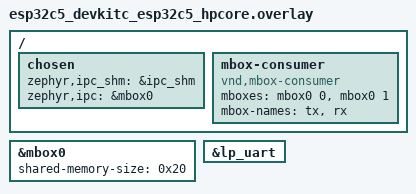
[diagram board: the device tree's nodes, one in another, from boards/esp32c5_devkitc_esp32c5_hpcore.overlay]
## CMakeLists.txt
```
# SPDX-License-Identifier: Apache-2.0

cmake_minimum_required(VERSION 3.20.0)
find_package(Zephyr REQUIRED HINTS $ENV{ZEPHYR_BASE})
project(zephyr_bist)

target_sources(app PRIVATE src/main.c)
```

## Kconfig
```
# Copyright (c) 2025 Espressif Systems (Shanghai) Co., Ltd.
# SPDX-License-Identifier: Apache-2.0

source "Kconfig.zephyr"

config INCLUDE_REMOTE_DIR
	bool "Include remote core header directory"
	help
	  Include remote build header files. Can be used if primary image
	  needs to be aware of size or base address of secondary image

config TX_ENABLED
	bool "TX enabled"
	default y
	help
	  Enable TX

config RX_ENABLED
	bool "RX enabled"
	default y
	help
	  Enable RX
```

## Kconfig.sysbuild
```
# Copyright (c) 2025 Espressif Systems (Shanghai) Co., Ltd.
# SPDX-License-Identifier: Apache-2.0

source "share/sysbuild/Kconfig"

config REMOTE_BOARD
	string "Remote board"
	default "esp32c6_devkitc/esp32c6/lpcore" if "$(BOARD)/${BOARD_QUALIFIERS}" = "esp32c6_devkitc/esp32c6/hpcore"
```

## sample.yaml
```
sample:
  name: ESP-BIST Host Diagnostics
  description: >
    LP-core Class B self-tests supervised from a Zephyr HP application, using
    the Host Diagnostic Agent and its LP companion.
common:
  sysbuild: true
  integration_platforms:
    - esp32c5_devkitc/esp32c5/hpcore
    - esp32c6_devkitc/esp32c6/hpcore
    - esp32p4x_function_ev_board/esp32p4/hpcore
  platform_allow:
    - esp32c5_devkitc/esp32c5/hpcore
    - esp32c6_devkitc/esp32c6/hpcore
    - esp32p4x_function_ev_board/esp32p4/hpcore
  tags:
    - bist
    - safety
tests:
  # Smoke test for the sample as shipped. The companion verdict is asserted in
  # tests/integration/hd_zephyr; here we only confirm the sample runs and
  # reports, so it stays a starting point rather than a test suite.
  sample.bist.host_diagnostics:
    harness: console
    harness_config:
      type: multi_line
      ordered: true
      regex:
        - "test_HD_agent_ready:PASS"
        - "test_BIST_cpu_reg:PASS"
        - "test_BIST_runtime_cpu_reg:PASS"
        - "Runtime loop 5/5"
        - "test_HD_audit_cpu:PASS"
        - "test_HD_audit_csr:PASS"
        - "test_HD_audit_ram:PASS"
        - "BIST_RESULT:PASS"
```

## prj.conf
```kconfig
CONFIG_MBOX=y
CONFIG_ESP32_ULP_COPROC_ENABLED=y
# Host Diagnostic Agent (HP side). LP runs the companion STL; HP compiles
# CPU/CSR/RAM STL slices when the matching HD audit is enabled.
CONFIG_ESP_BIST_HOST_DIAGNOSTICS=y
CONFIG_ESP_BIST_HD_AUDIT_QA=y
CONFIG_ESP_BIST_HD_AUDIT_CHECKPOINT=y
CONFIG_ESP_BIST_HD_AUDIT_IRQ_LATENCY=y
CONFIG_ESP_BIST_HD_AUDIT=y
CONFIG_ESP_BIST_HD_AUDIT_CPU=y
CONFIG_ESP_BIST_HD_AUDIT_CSR=y
CONFIG_ESP_BIST_HD_AUDIT_RAM=y
```

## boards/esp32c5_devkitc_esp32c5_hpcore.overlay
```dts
/*
 * Copyright (c) 2026 Espressif Systems (Shanghai) Co., Ltd.
 *
 * SPDX-License-Identifier: Apache-2.0
 */

/ {
	chosen {
		zephyr,ipc_shm = &ipc_shm;
		zephyr,ipc = &mbox0;
	};

	mbox-consumer {
		compatible = "vnd,mbox-consumer";
		mboxes = <&mbox0 0>, <&mbox0 1>;
		mbox-names = "tx", "rx";
	};
};

&mbox0 {
	status = "okay";
	/* One Host Diagnostics frame (4 words) per direction. */
	shared-memory-size = <0x20>;
};

&lp_uart {
	status = "okay";
};
```

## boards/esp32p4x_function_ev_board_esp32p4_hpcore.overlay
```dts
/*
 * Copyright (c) 2026 Espressif Systems (Shanghai) Co., Ltd.
 *
 * SPDX-License-Identifier: Apache-2.0
 */

/ {
	chosen {
		zephyr,ipc_shm = &ipc_shm;
		zephyr,ipc = &mbox0;
		zephyr,console = &uart0;
		zephyr,shell-uart = &uart0;
	};

	mbox-consumer {
		compatible = "vnd,mbox-consumer";
		mboxes = <&mbox0 0>, <&mbox0 1>;
		mbox-names = "tx", "rx";
	};
};

&mbox0 {
	status = "okay";
	shared-memory-size = <0x20>;
};

&lp_uart {
	status = "okay";
};
```

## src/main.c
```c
/*
 * Copyright (c) 2026 Espressif Systems (Shanghai) Co., Ltd.
 *
 * SPDX-License-Identifier: Apache-2.0
 */

/*
 * HP-core side of the ESP-BIST Zephyr sample.
 *
 * Starts the Host Diagnostic Agent, which sends AGENT_READY, queues the LP
 * companion status bitmasks and answers Q&A challenges on its worker thread.
 * The companion under remote/ does the actual testing; this side only reports.
 * Mirrors samples/idf/main/main.c so both platforms read the same way.
 *
 * This is the happy path only, so it stays readable as a starting point.
 * Fail-closed behaviour is validated in tests/integration/hd_zephyr, which
 * makes the host misbehave and observes the companion resetting it.
 */

#include <zephyr/kernel.h>

#include <bist_hd_agent.h>
#include <bist_hd_protocol.h>

/* Let the LP core boot and register its mbox callback before AGENT_READY. */
#define LP_BOOT_SETTLE_MS 200

#define STATUS_TIMEOUT_MS 10000
#define RUNTIME_LOOPS     5

/* Tests enabled on the LP core, from remote/prj.conf. */
#define POSTBOOT_EXPECTED                                                                          \
	(BIST_HD_BIT_CPU_REG | BIST_HD_BIT_RAM_X | BIST_HD_BIT_FLASH | BIST_HD_BIT_ABRAHAM)
#define RUNTIME_EXPECTED                                                                           \
	(BIST_HD_BIT_CPU_REG | BIST_HD_BIT_RAM_A | BIST_HD_BIT_STACK | BIST_HD_BIT_ABRAHAM)

static void print_postboot_results(uint32_t result)
{
	printk("=== Post-boot BIST results ===\n");
	printk("test_BIST_cpu_reg:%s\n", (result & BIST_HD_BIT_CPU_REG) ? "PASS" : "FAIL");
	printk("test_BIST_ram_march_x:%s\n", (result & BIST_HD_BIT_RAM_X) ? "PASS" : "FAIL");
	printk("test_BIST_ram_abraham:%s\n", (result & BIST_HD_BIT_ABRAHAM) ? "PASS" : "FAIL");
	printk("test_BIST_flash_crc:%s\n", (result & BIST_HD_BIT_FLASH) ? "PASS" : "FAIL");
}

static void print_runtime_results(uint32_t result)
{
	printk("=== Runtime BIST results ===\n");
	printk("test_BIST_runtime_cpu_reg:%s\n", (result & BIST_HD_BIT_CPU_REG) ? "PASS" : "FAIL");
	printk("test_BIST_runtime_ram_march_a:%s\n", (result & BIST_HD_BIT_RAM_A) ? "PASS" : "FAIL");
	printk("test_BIST_runtime_ram_abraham:%s\n",
	       (result & BIST_HD_BIT_ABRAHAM) ? "PASS" : "FAIL");
	printk("test_BIST_runtime_stack_check:%s\n", (result & BIST_HD_BIT_STACK) ? "PASS" : "FAIL");
}

int main(void)
{
	uint32_t status;
	bool all_pass = true;
	bool runtime_ok = true;
	int err;

	k_msleep(LP_BOOT_SETTLE_MS);

	err = bist_hd_agent_start();
	if (err != 0) {
		printk("Failed to start Host Diagnostic Agent: %d\n", err);
		printk("test_HD_agent_ready:FAIL\n");
		return 0;
	}
	printk("Host Diagnostic Agent started\n");
	printk("test_HD_agent_ready:PASS\n");

	err = bist_hd_agent_wait_lp_status(&status, BIST_HD_BIT_POSTBOOT, STATUS_TIMEOUT_MS);
	if (err == 0) {
		print_postboot_results(status);
		all_pass = (status & POSTBOOT_EXPECTED) == POSTBOOT_EXPECTED;
	} else {
		printk("test_BIST_postboot:TIMEOUT\n");
		all_pass = false;
	}

	for (int i = 1; i <= RUNTIME_LOOPS; i++) {
		err = bist_hd_agent_wait_lp_status(&status, BIST_HD_BIT_RUNTIME, STATUS_TIMEOUT_MS);
		if (err != 0) {
			printk("test_BIST_runtime:TIMEOUT (loop %d)\n", i);
			all_pass = false;
			runtime_ok = false;
			break;
		}
		printk("--- Runtime loop %d/%d ---\n", i, RUNTIME_LOOPS);
		print_runtime_results(status);
		if ((status & RUNTIME_EXPECTED) != RUNTIME_EXPECTED) {
			all_pass = false;
		}
		bist_hd_checkpoint_reached();
	}

	bist_hd_audit_result_t audit = {0};

	if (bist_hd_agent_audit_get(BIST_HD_AUDIT_CPU, &audit) != 0 || audit.valid == 0 ||
	    audit.status != BIST_HD_STATUS_OK) {
		all_pass = false;
		printk("test_HD_audit_cpu:FAIL\n");
	} else {
		printk("test_HD_audit_cpu:PASS\n");
	}
	if (bist_hd_agent_audit_get(BIST_HD_AUDIT_CSR, &audit) != 0 || audit.valid == 0 ||
	    audit.status != BIST_HD_STATUS_OK) {
		all_pass = false;
		printk("test_HD_audit_csr:FAIL\n");
	} else {
		printk("test_HD_audit_csr:PASS\n");
	}
	if (bist_hd_agent_audit_get(BIST_HD_AUDIT_RAM, &audit) != 0 || audit.valid == 0 ||
	    audit.status != BIST_HD_STATUS_OK) {
		all_pass = false;
		printk("test_HD_audit_ram:FAIL\n");
	} else {
		printk("test_HD_audit_ram:PASS\n");
	}

	if (IS_ENABLED(CONFIG_ESP_BIST_HD_AUDIT_QA)) {
		/*
		 * Completing all runtime loops proves Q&A rounds passed; a
		 * runtime test failure does not invalidate Q&A.
		 */
		printk("test_HD_challenge:%s\n", runtime_ok ? "PASS" : "FAIL");
	}

	if (IS_ENABLED(CONFIG_ESP_BIST_HD_AUDIT_CHECKPOINT)) {
		/*
		 * Completing all loops proves every checkpoint was accepted
		 * by the companion.
		 */
		printk("test_HD_checkpoint:%s\n", runtime_ok ? "PASS" : "FAIL");
	}

	printk("BIST_RESULT:%s\n", all_pass ? "PASS" : "FAIL");

	/*
	 * The agent thread keeps receiving companion messages (runtime status
	 * and optional host-audit traffic). Park main so the sample stays up.
	 */
	while (1) {
		k_msleep(10);
		bist_hd_checkpoint_reached();
	}

	return 0;
}
```
